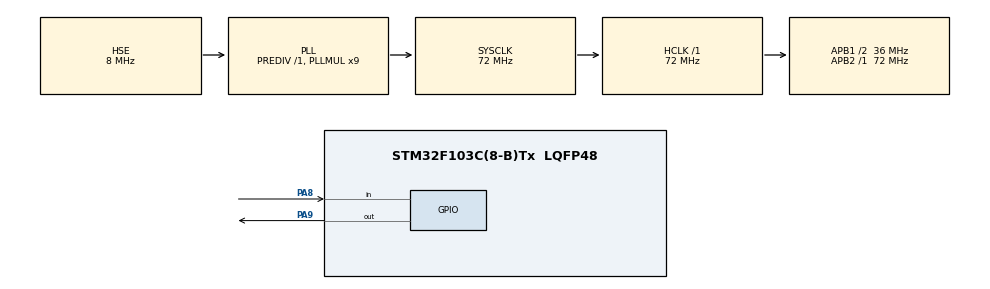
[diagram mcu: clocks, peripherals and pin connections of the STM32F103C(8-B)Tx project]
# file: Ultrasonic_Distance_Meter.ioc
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Mcu.Family=STM32F1
Mcu.Name=STM32F103C(8-B)Tx
Mcu.Package=LQFP48
NVIC.PriorityGroup=NVIC_PRIORITYGROUP_4
PA13.Mode=Serial_Wire
PA13.Signal=SYS_JTMS-SWDIO
PA14.Mode=Serial_Wire
PA14.Signal=SYS_JTCK-SWCLK
PA8.Signal=GPIO_Input
PA9.Signal=GPIO_Output
PD0-OSC_IN.Mode=HSE-External-Oscillator
PD0-OSC_IN.Signal=RCC_OSC_IN
PD1-OSC_OUT.Mode=HSE-External-Oscillator
PD1-OSC_OUT.Signal=RCC_OSC_OUT
ProjectManager.HeapSize=0x200
ProjectManager.StackSize=0x400
ProjectManager.TargetToolchain=EWARM V8.32
RCC.AHBFreq_Value=72000000
RCC.APB1CLKDivider=RCC_HCLK_DIV2
RCC.APB1Freq_Value=36000000
RCC.APB1TimFreq_Value=72000000
RCC.APB2Freq_Value=72000000
RCC.APB2TimFreq_Value=72000000
RCC.HCLKFreq_Value=72000000
RCC.PLLMUL=RCC_PLL_MUL9
RCC.PLLSourceVirtual=RCC_PLLSOURCE_HSE
RCC.SYSCLKFreq_VALUE=72000000
RCC.SYSCLKSource=RCC_SYSCLKSOURCE_PLLCLK
RCC.USBFreq_Value=72000000
TIM1.Prescaler=71
VP_TIM1_VS_ClockSourceINT.Mode=Internal
board=custom

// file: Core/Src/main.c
/* USER CODE BEGIN Header */
/**
 ******************************************************************************
 * @file           : main.c
 * @brief          : Main program body
 ******************************************************************************
 * @attention
 *
 * Copyright (c) 2026 STMicroelectronics.
 * All rights reserved.
 *
 * This software is licensed under terms that can be found in the LICENSE file
 * in the root directory of this software component.
 * If no LICENSE file comes with this software, it is provided AS-IS.
 *
 ******************************************************************************
 */
/* USER CODE END Header */
#include "main.h"

TIM_HandleTypeDef htim1;

/* USER CODE BEGIN PV */
#define TRIG_PIN GPIO_PIN_9
#define TRIG_PORT GPIOA
#define ECHO_PIN GPIO_PIN_8
#define ECHO_PORT GPIOA

uint32_t pMillis;      /* Tick snapshot used for timeout guards      */
uint32_t Value1 = 0;   /* Timer count when ECHO goes HIGH (start)     */
uint32_t Value2 = 0;   /* Timer count when ECHO goes LOW  (end)       */
uint16_t Distance = 0; /* Calculated distance in cm                   */
/* USER CODE END PV */

void SystemClock_Config(void);
static void MX_GPIO_Init(void);
static void MX_TIM1_Init(void);

int main(void)
{

  /* MCU Configuration--------------------------------------------------------*/

  /* Reset of all peripherals, Initializes the Flash interface and the Systick. */
  HAL_Init();

  /* Configure the system clock */
  SystemClock_Config();

  /* Initialize all configured peripherals */
  MX_GPIO_Init();
  MX_TIM1_Init();
  /* USER CODE BEGIN 2 */
  HAL_TIM_Base_Start(&htim1);
  HAL_GPIO_WritePin(TRIG_PORT, TRIG_PIN,
                    GPIO_PIN_RESET); /* ensure TRIG starts LOW */
  /* USER CODE END 2 */

  /* Infinite loop */
  while (1) {

    /* USER CODE BEGIN 3 */

    /* ---- 1. Send 10 µs TRIG pulse ---------------------------------------- */
    HAL_GPIO_WritePin(TRIG_PORT, TRIG_PIN, GPIO_PIN_SET);
    __HAL_TIM_SET_COUNTER(&htim1, 0);
    while (__HAL_TIM_GET_COUNTER(&htim1) < 10)
      ; /* wait exactly 10 µs */
    HAL_GPIO_WritePin(TRIG_PORT, TRIG_PIN, GPIO_PIN_RESET);

    /* ---- 2. Wait for ECHO to go HIGH (timeout 10 ms) --------------------- */
    pMillis = HAL_GetTick();
    while (!(HAL_GPIO_ReadPin(ECHO_PORT, ECHO_PIN)) &&
           (pMillis + 10 > HAL_GetTick()))
      ;
    Value1 = __HAL_TIM_GET_COUNTER(&htim1);

    /* ---- 3. Wait for ECHO to go LOW (timeout 50 ms) ---------------------- */
    pMillis = HAL_GetTick();
    while ((HAL_GPIO_ReadPin(ECHO_PORT, ECHO_PIN)) &&
           (pMillis + 50 > HAL_GetTick()))
      ;
    Value2 = __HAL_TIM_GET_COUNTER(&htim1);

    /* ---- 4. Calculate distance ------------------------------------------- */
    /* Distance (cm) = pulse_time_µs * 0.034 / 2                              */
    /* 0.034 cm/µs = speed of sound (34000 cm/s) expressed per microsecond   */
    /* divide by 2 because the pulse is a round-trip (to object and back)     */
    Distance = (Value2 - Value1) * 0.034 / 2;

    /* ---- 5. 50 ms between measurements (avoids echo cross-talk) ---------- */
    HAL_Delay(50);
  }
  /* USER CODE END 3 */
}

void SystemClock_Config(void)
{
  RCC_OscInitTypeDef RCC_OscInitStruct = {0};
  RCC_ClkInitTypeDef RCC_ClkInitStruct = {0};

  /** Initializes the RCC Oscillators according to the specified parameters
  * in the RCC_OscInitTypeDef structure.
  */
  RCC_OscInitStruct.OscillatorType = RCC_OSCILLATORTYPE_HSE;
  RCC_OscInitStruct.HSEState = RCC_HSE_ON;
  RCC_OscInitStruct.HSEPredivValue = RCC_HSE_PREDIV_DIV1;
  RCC_OscInitStruct.HSIState = RCC_HSI_ON;
  RCC_OscInitStruct.PLL.PLLState = RCC_PLL_ON;
  RCC_OscInitStruct.PLL.PLLSource = RCC_PLLSOURCE_HSE;
  RCC_OscInitStruct.PLL.PLLMUL = RCC_PLL_MUL9;
  if (HAL_RCC_OscConfig(&RCC_OscInitStruct) != HAL_OK)
  {
    Error_Handler();
  }

  /** Initializes the CPU, AHB and APB buses clocks
  */
  RCC_ClkInitStruct.ClockType = RCC_CLOCKTYPE_HCLK|RCC_CLOCKTYPE_SYSCLK
                              |RCC_CLOCKTYPE_PCLK1|RCC_CLOCKTYPE_PCLK2;
  RCC_ClkInitStruct.SYSCLKSource = RCC_SYSCLKSOURCE_PLLCLK;
  RCC_ClkInitStruct.AHBCLKDivider = RCC_SYSCLK_DIV1;
  RCC_ClkInitStruct.APB1CLKDivider = RCC_HCLK_DIV2;
  RCC_ClkInitStruct.APB2CLKDivider = RCC_HCLK_DIV1;

  if (HAL_RCC_ClockConfig(&RCC_ClkInitStruct, FLASH_LATENCY_2) != HAL_OK)
  {
    Error_Handler();
  }
}

static void MX_TIM1_Init(void)
{

  TIM_ClockConfigTypeDef sClockSourceConfig = {0};
  TIM_MasterConfigTypeDef sMasterConfig = {0};

  htim1.Instance = TIM1;
  htim1.Init.Prescaler = 71;
  htim1.Init.CounterMode = TIM_COUNTERMODE_UP;
  htim1.Init.Period = 65535;
  htim1.Init.ClockDivision = TIM_CLOCKDIVISION_DIV1;
  htim1.Init.RepetitionCounter = 0;
  htim1.Init.AutoReloadPreload = TIM_AUTORELOAD_PRELOAD_DISABLE;
  if (HAL_TIM_Base_Init(&htim1) != HAL_OK)
  {
    Error_Handler();
  }
  sClockSourceConfig.ClockSource = TIM_CLOCKSOURCE_INTERNAL;
  if (HAL_TIM_ConfigClockSource(&htim1, &sClockSourceConfig) != HAL_OK)
  {
    Error_Handler();
  }
  sMasterConfig.MasterOutputTrigger = TIM_TRGO_RESET;
  sMasterConfig.MasterSlaveMode = TIM_MASTERSLAVEMODE_DISABLE;
  if (HAL_TIMEx_MasterConfigSynchronization(&htim1, &sMasterConfig) != HAL_OK)
  {
    Error_Handler();
  }

}

static void MX_GPIO_Init(void)
{
  GPIO_InitTypeDef GPIO_InitStruct = {0};

  /* GPIO Ports Clock Enable */
  __HAL_RCC_GPIOD_CLK_ENABLE();
  __HAL_RCC_GPIOA_CLK_ENABLE();

  /*Configure GPIO pin Output Level */
  HAL_GPIO_WritePin(GPIOA, GPIO_PIN_9, GPIO_PIN_RESET);

  /*Configure GPIO pin : PA8 */
  GPIO_InitStruct.Pin = GPIO_PIN_8;
  GPIO_InitStruct.Mode = GPIO_MODE_INPUT;
  GPIO_InitStruct.Pull = GPIO_NOPULL;
  HAL_GPIO_Init(GPIOA, &GPIO_InitStruct);

  /*Configure GPIO pin : PA9 */
  GPIO_InitStruct.Pin = GPIO_PIN_9;
  GPIO_InitStruct.Mode = GPIO_MODE_OUTPUT_PP;
  GPIO_InitStruct.Pull = GPIO_NOPULL;
  GPIO_InitStruct.Speed = GPIO_SPEED_FREQ_LOW;
  HAL_GPIO_Init(GPIOA, &GPIO_InitStruct);

}

/* USER CODE BEGIN 4 */

/**
 * @brief  USART2 Initialization Function
 *         PA2 = TX  (connect to RX of USB-TTL adapter)
 *         PA3 = RX  (optional, leave unconnected if not used)
 *         Baud rate : 115200
 * @retval None
 */
static void MX_USART2_UART_Init(void) {
  __HAL_RCC_USART2_CLK_ENABLE();
  __HAL_RCC_GPIOA_CLK_ENABLE();

  /* PA2 -> USART2_TX (Alternate Function Push-Pull) */
  GPIO_InitTypeDef gpio = {0};
  gpio.Pin = GPIO_PIN_2;
  gpio.Mode = GPIO_MODE_AF_PP;
  gpio.Speed = GPIO_SPEED_FREQ_HIGH;
  HAL_GPIO_Init(GPIOA, &gpio);

  /* PA3 -> USART2_RX (Input Floating) */
  gpio.Pin = GPIO_PIN_3;
  gpio.Mode = GPIO_MODE_INPUT;
  gpio.Pull = GPIO_NOPULL;
  HAL_GPIO_Init(GPIOA, &gpio);

  huart2.Instance = USART2;
  huart2.Init.BaudRate = 115200;
  huart2.Init.WordLength = UART_WORDLENGTH_8B;
  huart2.Init.StopBits = UART_STOPBITS_1;
  huart2.Init.Parity = UART_PARITY_NONE;
  huart2.Init.Mode = UART_MODE_TX_RX;
  huart2.Init.HwFlowCtl = UART_HWCONTROL_NONE;
  huart2.Init.OverSampling = UART_OVERSAMPLING_16;

  if (HAL_UART_Init(&huart2) != HAL_OK) {
    Error_Handler();
  }
}

/* USER CODE END 4 */

void Error_Handler(void)
{
  __disable_irq();
  while (1) {
  }
}
#ifdef USE_FULL_ASSERT
/**
  * @brief  Reports the name of the source file and the source line number
  *         where the assert_param error has occurred.
  * @param  file: pointer to the source file name
  * @param  line: assert_param error line source number
  * @retval None
  */
void assert_failed(uint8_t *file, uint32_t line)
{
  /* USER CODE BEGIN 6 */
  /* User can add his own implementation to report the file name and line
     number, ex: printf("Wrong parameters value: file %s on line %d\r\n", file,
     line) */
  /* USER CODE END 6 */
}
#endif /* USE_FULL_ASSERT */
